AUTOSAR XML (schema 4-2-2)
package /SysDesc/Pkg_Cluster
  can cluster Can_Network_ETAS: baudrate=500000, protocol-name=CAN, protocol-version=1.0, bus-off-recovery={bor-counter-l-1-to-l-2=32, bor-time-l-1=0.01, bor-time-l-2=60.0, bor-time-tx-ensured=1.0, main-function-period=0.001}
    can physical channel Can_Network_ETAS_Channel: comm-connectors=Conn_ETAS_CAN_ETAS
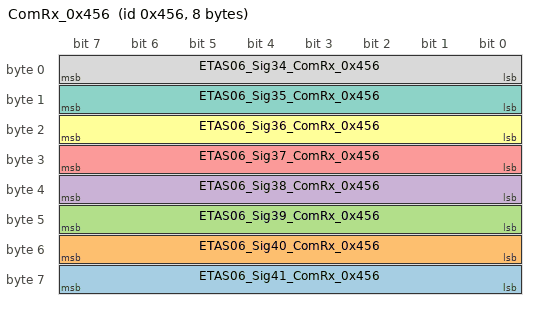
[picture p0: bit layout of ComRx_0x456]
      frame ComRx_0x456: id 0x456, to ETAS, frame-length=8, can-addressing-mode=STANDARD, can-frame-rx-behavior=ANY
        carries pdu ComRx_0x456: packing-byte-order=big-endian, start-position=7, update-indication-bit-position=-1
        pdu ComRx_0x456: length=8, transmission-mode-false-timing=cyclic-timing={time-offset=0, time-period=0.01}, transmission-mode-true-timing=cyclic-timing={time-offset=0, time-period=0.01}
          transmission-mode-conditions:
            {data-filter={data-filter-type=ALWAYS, max=0, min=0, offset=0}, i-signal-in-i-pdu=ETAS06_Sig41}
            {data-filter={data-filter-type=ALWAYS, max=0, min=0, offset=0}, i-signal-in-i-pdu=ETAS06_Sig40}
            {data-filter={data-filter-type=ALWAYS, max=0, min=0, offset=0}, i-signal-in-i-pdu=ETAS06_Sig39}
            {data-filter={data-filter-type=ALWAYS, max=0, min=0, offset=0}, i-signal-in-i-pdu=ETAS06_Sig38}
            {data-filter={data-filter-type=ALWAYS, max=0, min=0, offset=0}, i-signal-in-i-pdu=ETAS06_Sig37}
            {data-filter={data-filter-type=ALWAYS, max=0, min=0, offset=0}, i-signal-in-i-pdu=ETAS06_Sig36}
            {data-filter={data-filter-type=ALWAYS, max=0, min=0, offset=0}, i-signal-in-i-pdu=ETAS06_Sig35}
            {data-filter={data-filter-type=ALWAYS, max=0, min=0, offset=0}, i-signal-in-i-pdu=ETAS06_Sig34}
          signal ETAS06_Sig41_ComRx_0x456: start 63, 8 bit, big-endian, init-value=0, base-type=uint8, compu {phys=raw for raw 0}, update-indication-bit-position=-1, to ETAS
          signal ETAS06_Sig40_ComRx_0x456: start 55, 8 bit, big-endian, init-value=0, base-type=uint8, compu {phys=raw for raw 0}, update-indication-bit-position=-1, to ETAS
          signal ETAS06_Sig39_ComRx_0x456: start 47, 8 bit, big-endian, init-value=0, base-type=uint8, compu {phys=raw for raw 0}, update-indication-bit-position=-1, to ETAS
          signal ETAS06_Sig38_ComRx_0x456: start 39, 8 bit, big-endian, init-value=0, base-type=uint8, compu {phys=raw for raw 0}, update-indication-bit-position=-1, to ETAS
          signal ETAS06_Sig37_ComRx_0x456: start 31, 8 bit, big-endian, init-value=0, base-type=uint8, compu {phys=raw for raw 0}, update-indication-bit-position=-1, to ETAS
          signal ETAS06_Sig36_ComRx_0x456: start 23, 8 bit, big-endian, init-value=0, base-type=uint8, compu {phys=raw for raw 0}, update-indication-bit-position=-1, to ETAS
          signal ETAS06_Sig35_ComRx_0x456: start 15, 8 bit, big-endian, init-value=0, base-type=uint8, compu {phys=raw for raw 0}, update-indication-bit-position=-1, to ETAS
          signal ETAS06_Sig34_ComRx_0x456: start 7, 8 bit, big-endian, init-value=0, base-type=uint8, compu {phys=raw for raw 0}, update-indication-bit-position=-1, to ETAS
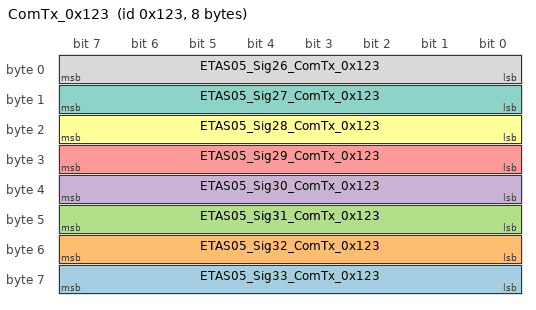
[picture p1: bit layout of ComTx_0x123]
      frame ComTx_0x123: id 0x123, from ETAS, frame-length=8, can-addressing-mode=STANDARD, can-frame-tx-behavior=CAN-20
        carries pdu ComTx_0x123: packing-byte-order=big-endian, start-position=7, update-indication-bit-position=-1
        pdu ComTx_0x123: length=8, transmission-mode-false-timing=cyclic-timing={time-offset=0, time-period=0.1}, transmission-mode-true-timing=cyclic-timing={time-offset=0, time-period=0.1}
          transmission-mode-conditions:
            {data-filter={data-filter-type=ALWAYS, max=0, min=0, offset=0}, i-signal-in-i-pdu=ETAS05_Sig33}
            {data-filter={data-filter-type=ALWAYS, max=0, min=0, offset=0}, i-signal-in-i-pdu=ETAS05_Sig32}
            {data-filter={data-filter-type=ALWAYS, max=0, min=0, offset=0}, i-signal-in-i-pdu=ETAS05_Sig31}
            {data-filter={data-filter-type=ALWAYS, max=0, min=0, offset=0}, i-signal-in-i-pdu=ETAS05_Sig30}
            {data-filter={data-filter-type=ALWAYS, max=0, min=0, offset=0}, i-signal-in-i-pdu=ETAS05_Sig29}
            {data-filter={data-filter-type=ALWAYS, max=0, min=0, offset=0}, i-signal-in-i-pdu=ETAS05_Sig28}
            {data-filter={data-filter-type=ALWAYS, max=0, min=0, offset=0}, i-signal-in-i-pdu=ETAS05_Sig27}
            {data-filter={data-filter-type=ALWAYS, max=0, min=0, offset=0}, i-signal-in-i-pdu=ETAS05_Sig26}
          signal ETAS05_Sig33_ComTx_0x123: start 63, 8 bit, big-endian, init-value=0, base-type=uint8, compu {phys=raw for raw 0}, update-indication-bit-position=-1
          signal ETAS05_Sig32_ComTx_0x123: start 55, 8 bit, big-endian, init-value=0, base-type=uint8, compu {phys=raw for raw 0}, update-indication-bit-position=-1
          signal ETAS05_Sig31_ComTx_0x123: start 47, 8 bit, big-endian, init-value=0, base-type=uint8, compu {phys=raw for raw 0}, update-indication-bit-position=-1
          signal ETAS05_Sig30_ComTx_0x123: start 39, 8 bit, big-endian, init-value=0, base-type=uint8, compu {phys=raw for raw 0}, update-indication-bit-position=-1
          signal ETAS05_Sig29_ComTx_0x123: start 31, 8 bit, big-endian, init-value=0, base-type=uint8, compu {phys=raw for raw 0}, update-indication-bit-position=-1
          signal ETAS05_Sig28_ComTx_0x123: start 23, 8 bit, big-endian, init-value=0, base-type=uint8, compu {phys=raw for raw 0}, update-indication-bit-position=-1
          signal ETAS05_Sig27_ComTx_0x123: start 15, 8 bit, big-endian, init-value=0, base-type=uint8, compu {phys=raw for raw 0}, update-indication-bit-position=-1
          signal ETAS05_Sig26_ComTx_0x123: start 7, 8 bit, big-endian, init-value=0, base-type=uint8, compu {phys=raw for raw 0}, update-indication-bit-position=-1
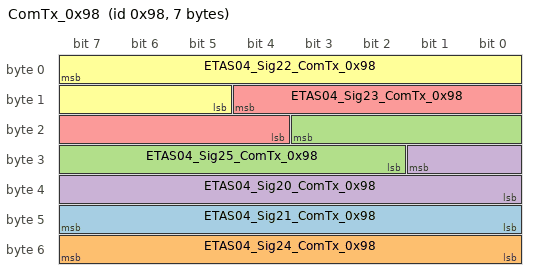
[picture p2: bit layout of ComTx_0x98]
      frame ComTx_0x98: id 0x98, from ETAS, frame-length=7, can-addressing-mode=STANDARD, can-frame-tx-behavior=CAN-20
        carries pdu ComTx_0x98: packing-byte-order=big-endian, start-position=7, update-indication-bit-position=-1
        pdu ComTx_0x98: length=7, transmission-mode-false-timing=cyclic-timing={time-offset=0, time-period=0.05}, transmission-mode-true-timing=cyclic-timing={time-offset=0, time-period=0.05}
          transmission-mode-conditions:
            {data-filter={data-filter-type=NEW-IS-WITHIN, max=254, min=0, offset=0}, i-signal-in-i-pdu=ETAS04_Sig21}
            {data-filter={data-filter-type=NEW-IS-WITHIN, max=254, min=0, offset=0}, i-signal-in-i-pdu=ETAS04_Sig24}
            {data-filter={data-filter-type=NEW-IS-WITHIN, max=1022, min=0, offset=0}, i-signal-in-i-pdu=ETAS04_Sig25}
            {data-filter={data-filter-type=NEW-IS-WITHIN, max=1022, min=0, offset=0}, i-signal-in-i-pdu=ETAS04_Sig20}
            {data-filter={data-filter-type=NEW-IS-WITHIN, max=510, min=0, offset=0}, i-signal-in-i-pdu=ETAS04_Sig23}
            {data-filter={data-filter-type=NEW-IS-WITHIN, max=2046, min=0, offset=0}, i-signal-in-i-pdu=ETAS04_Sig22}
          signal ETAS04_Sig21_ComTx_0x98: start 47, 8 bit, big-endian, init-value=40, base-type=uint8, compu {phys=raw-40 for raw 0..254; unit deg}, update-indication-bit-position=-1  # IGBT温度
          signal ETAS04_Sig24_ComTx_0x98: start 55, 8 bit, big-endian, init-value=40, base-type=uint8, compu {phys=raw-40 for raw 0..254; unit deg}, update-indication-bit-position=-1  # 电机温度
          signal ETAS04_Sig25_ComTx_0x98: start 19, 10 bit, big-endian, init-value=0, base-type=uint16, compu {phys=raw for raw 0..1022; unit V}, update-indication-bit-position=-1  # 母线电压
          signal ETAS04_Sig20_ComTx_0x98: start 25, 10 bit, big-endian, init-value=511, base-type=uint16, compu {phys=raw-511 for raw 0..1022; unit A}, update-indication-bit-position=-1  # 母线电流
          signal ETAS04_Sig23_ComTx_0x98: start 12, 9 bit, big-endian, init-value=0, base-type=uint16, compu {phys=raw for raw 0..510; unit Nm}, update-indication-bit-position=-1  # 最小扭矩
          signal ETAS04_Sig22_ComTx_0x98: start 7, 11 bit, big-endian, init-value=0, base-type=uint16, compu {phys=raw for raw 0..2046; unit Nm}, update-indication-bit-position=-1  # 最大扭矩
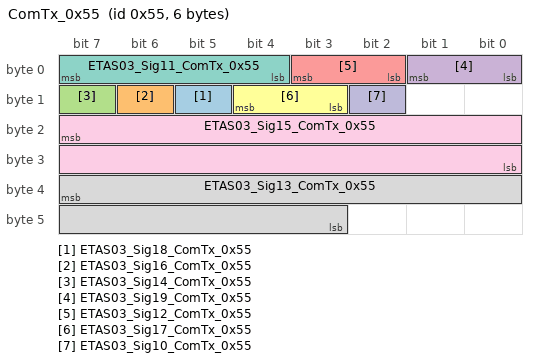
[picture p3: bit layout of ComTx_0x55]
      frame ComTx_0x55: id 0x55, from ETAS, frame-length=6, can-addressing-mode=STANDARD, can-frame-tx-behavior=CAN-20
        carries pdu ComTx_0x55: packing-byte-order=big-endian, start-position=7, update-indication-bit-position=-1
        pdu ComTx_0x55: length=6, transmission-mode-false-timing=cyclic-timing={time-offset=0, time-period=0.01}, transmission-mode-true-timing=cyclic-timing={time-offset=0, time-period=0.01}
          transmission-mode-conditions:
            {data-filter={data-filter-type=ALWAYS, max=1, min=0, offset=0}, i-signal-in-i-pdu=ETAS03_Sig18}
            {data-filter={data-filter-type=ALWAYS, max=1, min=0, offset=0}, i-signal-in-i-pdu=ETAS03_Sig16}
            {data-filter={data-filter-type=ALWAYS, max=1, min=0, offset=0}, i-signal-in-i-pdu=ETAS03_Sig14}
            {data-filter={data-filter-type=ALWAYS, max=3, min=0, offset=0}, i-signal-in-i-pdu=ETAS03_Sig19}
            {data-filter={data-filter-type=ALWAYS, max=3, min=0, offset=0}, i-signal-in-i-pdu=ETAS03_Sig12}
            {data-filter={data-filter-type=ALWAYS, max=3, min=0, offset=0}, i-signal-in-i-pdu=ETAS03_Sig17}
            {data-filter={data-filter-type=ALWAYS, max=3, min=0, offset=0}, i-signal-in-i-pdu=ETAS03_Sig11}
            {data-filter={data-filter-type=NEW-IS-WITHIN, max=8189, min=0, offset=0}, i-signal-in-i-pdu=ETAS03_Sig13}
            {data-filter={data-filter-type=NEW-IS-WITHIN, max=65534, min=0, offset=0}, i-signal-in-i-pdu=ETAS03_Sig15}
            {data-filter={data-filter-type=ALWAYS, max=1, min=0, offset=0}, i-signal-in-i-pdu=ETAS03_Sig10}
          signal ETAS03_Sig18_ComTx_0x55: start 13, 1 bit, big-endian, init-value=0, base-type=uint8, compu {phys=raw for raw 0..1, 0=FORBIDDING, 1=ALLOWING}, update-indication-bit-position=-1  # 允许下电
          signal ETAS03_Sig16_ComTx_0x55: start 14, 1 bit, big-endian, init-value=0, base-type=uint8, compu-method=CompuMethod_ETAS03_Sig16_ComTx_0x55, update-indication-bit-position=-1  # 高压上电完成
          signal ETAS03_Sig14_ComTx_0x55: start 15, 1 bit, big-endian, init-value=0, base-type=uint8, compu {phys=raw for raw 0..1, 0=FORBIDDINGTOTURNONHV, 1=ALLOWINGTOTURNONHV}, update-indication-bit-position=-1  # 允许高压上电
          signal ETAS03_Sig19_ComTx_0x55: start 1, 2 bit, big-endian, init-value=0, base-type=uint8, compu-method=CompuMethod_ETAS03_Sig19_ComTx_0x55, update-indication-bit-position=-1  # 电机工作状态
          signal ETAS03_Sig12_ComTx_0x55: start 3, 2 bit, big-endian, init-value=0, base-type=uint8, compu-method=CompuMethod_ETAS03_Sig12_ComTx_0x55, update-indication-bit-position=-1  # 电机快速放电状态
          signal ETAS03_Sig17_ComTx_0x55: start 12, 2 bit, big-endian, init-value=0, base-type=uint8, compu {phys=raw for raw 0..3, 0=DEFAULT, 1=SIG16ING, 2=OK, 3=FAILED}, update-indication-bit-position=-1  # MCU自检
          signal ETAS03_Sig11_ComTx_0x55: start 7, 4 bit, big-endian, init-value=0, base-type=uint8, compu {phys=raw for raw 0..3}, update-indication-bit-position=-1  # 报文滚码信息
          signal ETAS03_Sig13_ComTx_0x55: start 39, 13 bit, big-endian, init-value=4094, base-type=uint16, compu {phys=raw*0.5-2047 for raw 0..8189; unit Nm}, update-indication-bit-position=-1  # 电机当前扭矩
          signal ETAS03_Sig15_ComTx_0x55: start 23, 16 bit, big-endian, init-value=32767, base-type=uint16, compu {phys=raw-32767 for raw 0..65534; unit rpm}, update-indication-bit-position=-1  # 电机当前转速
          signal ETAS03_Sig10_ComTx_0x55: start 10, 1 bit, big-endian, init-value=0, base-type=uint8, compu {phys=raw for raw 0..1, 0=NORMAL, 1=SIG04}, update-indication-bit-position=-1  # 紧急下电请求
      frame ComRx_0x261: id 0x261, to ETAS, frame-length=1, can-addressing-mode=STANDARD, can-frame-rx-behavior=ANY
        carries pdu ComRx_0x261: packing-byte-order=big-endian, start-position=7, update-indication-bit-position=-1
        pdu ComRx_0x261: length=1, transmission-mode-condition{data-filter={data-filter-type=ALWAYS, max=1, min=0, offset=0}, i-signal-in-i-pdu=ETAS02_Sig09}, transmission-mode-false-timing=cyclic-timing={time-offset=0, time-period=0.01}, transmission-mode-true-timing=cyclic-timing={time-offset=0, time-period=0.01}
          signal ETAS02_Sig09_ComRx_0x261: start 0, 1 bit, big-endian, init-value=0, base-type=uint8, compu {phys=raw for raw 0..1, 0=NORMAL, 1=SLEEP}, update-indication-bit-position=-1, to ETAS  # ETAS低压下电
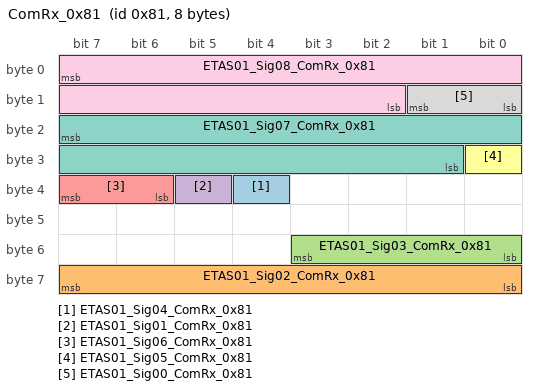
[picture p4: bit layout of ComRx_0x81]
      frame ComRx_0x81: id 0x81, to ETAS, frame-length=8, can-addressing-mode=STANDARD, can-frame-rx-behavior=ANY
        carries pdu ComRx_0x81: packing-byte-order=big-endian, start-position=7, update-indication-bit-position=-1
        pdu ComRx_0x81: length=8, transmission-mode-false-timing=cyclic-timing={time-offset=0, time-period=0.01}, transmission-mode-true-timing=cyclic-timing={time-offset=0, time-period=0.01}
          transmission-mode-conditions:
            {data-filter={data-filter-type=ALWAYS, max=1, min=0, offset=0}, i-signal-in-i-pdu=ETAS01_Sig04}
            {data-filter={data-filter-type=ALWAYS, max=255, min=0, offset=0}, i-signal-in-i-pdu=ETAS01_Sig02}
            {data-filter={data-filter-type=ALWAYS, max=15, min=0, offset=0}, i-signal-in-i-pdu=ETAS01_Sig03}
            {data-filter={data-filter-type=ALWAYS, max=1, min=0, offset=0}, i-signal-in-i-pdu=ETAS01_Sig01}
            {data-filter={data-filter-type=ALWAYS, max=3, min=0, offset=0}, i-signal-in-i-pdu=ETAS01_Sig06}
            {data-filter={data-filter-type=ALWAYS, max=1, min=0, offset=0}, i-signal-in-i-pdu=ETAS01_Sig05}
            {data-filter={data-filter-type=NEW-IS-WITHIN, max=32767, min=0, offset=0}, i-signal-in-i-pdu=ETAS01_Sig07}
            {data-filter={data-filter-type=ALWAYS, max=3, min=0, offset=0}, i-signal-in-i-pdu=ETAS01_Sig00}
            {data-filter={data-filter-type=NEW-IS-WITHIN, max=16383, min=0, offset=0}, i-signal-in-i-pdu=ETAS01_Sig08}
          signal ETAS01_Sig04_ComRx_0x81: start 36, 1 bit, big-endian, init-value=0, base-type=uint8, compu {phys=raw for raw 0..1, 0=FORBIDDING, 1=ALLOWING}, update-indication-bit-position=-1, to ETAS  # MCU使能信号
          signal ETAS01_Sig02_ComRx_0x81: start 63, 8 bit, big-endian, init-value=0, base-type=uint8, compu {phys=raw for raw 0..255}, update-indication-bit-position=-1, to ETAS  # 检查
          signal ETAS01_Sig03_ComRx_0x81: start 51, 4 bit, big-endian, init-value=0, base-type=uint8, compu {phys=raw for raw 0..15}, update-indication-bit-position=-1, to ETAS  # 滚码信息
          signal ETAS01_Sig01_ComRx_0x81: start 37, 1 bit, big-endian, init-value=0, base-type=uint8, compu {phys=raw for raw 0..1, 0=FORBIDDING, 1=ALLOWING}, update-indication-bit-position=-1, to ETAS  # MCU主动放电
          signal ETAS01_Sig06_ComRx_0x81: start 39, 2 bit, big-endian, init-value=0, base-type=uint8, compu-method=CompuMethod_ETAS01_Sig06_ComRx_0x81, update-indication-bit-position=-1, to ETAS  # 电机工作模式请求
          signal ETAS01_Sig05_ComRx_0x81: start 24, 1 bit, big-endian, init-value=0, base-type=uint8, compu {phys=raw for raw 0..1, 0=FORBIDDING, 1=ALLOWING}, update-indication-bit-position=-1, to ETAS  # MCU使能信号
          signal ETAS01_Sig07_ComRx_0x81: start 23, 15 bit, big-endian, init-value=16384, base-type=uint16, compu {phys=raw-16384 for raw 0..32767; unit rpm}, update-indication-bit-position=-1, to ETAS  # 需求转速
          signal ETAS01_Sig00_ComRx_0x81: start 9, 2 bit, big-endian, init-value=0, base-type=uint8, compu {phys=raw for raw 0..3, 0=N, 1=R, 2=D, 3=P}, update-indication-bit-position=-1, to ETAS  # 当前整车档位信息
          signal ETAS01_Sig08_ComRx_0x81: start 7, 14 bit, big-endian, init-value=8192, base-type=uint16, compu {phys=raw*0.25-2048 for raw 0..16383; unit Nm}, update-indication-bit-position=-1, to ETAS  # ETAS对MCU扭矩请求
      frame NM_Rx_0x677: id 0x677, to ETAS, frame-length=8, can-addressing-mode=STANDARD, can-frame-rx-behavior=ANY
        carries pdu NM_Rx_0x677: packing-byte-order=big-endian, start-position=7, update-indication-bit-position=-1
        nm pdu NM_Rx_0x677: length=8, nm-data-information=false, nm-vote-information=false
          signal NM_Rx_Sig_NM_Rx_0x677: start 23, 8 bit, big-endian, init-value=0, base-type=uint8, compu {phys=raw for raw 0..255}, update-indication-bit-position=-1, to ETAS
      frame NM_Tx_0x600: id 0x600, from ETAS, frame-length=8, can-addressing-mode=STANDARD, can-frame-tx-behavior=CAN-20
        carries pdu NM_Tx_0x600: packing-byte-order=big-endian, start-position=7, update-indication-bit-position=-1
        nm pdu NM_Tx_0x600: length=8, nm-data-information=false, nm-vote-information=false
          signal NM_Tx_Sig_NM_Tx_0x600: start 23, 8 bit, big-endian, init-value=0, base-type=uint8, compu {phys=raw for raw 0..255}, update-indication-bit-position=-1
      frame XcpTx_0x333: id 0x333, from ETAS, frame-length=8, can-addressing-mode=STANDARD, can-frame-tx-behavior=CAN-20
        carries pdu XcpTx_0x333: packing-byte-order=big-endian, start-position=7, update-indication-bit-position=-1
        general purpose i pdu XcpTx_0x333: category=XCP, length=8
      frame XcpRx_0x332: id 0x332, to ETAS, frame-length=8, can-addressing-mode=STANDARD, can-frame-rx-behavior=ANY
        carries pdu XcpRx_0x332: packing-byte-order=big-endian, start-position=7, update-indication-bit-position=-1
        general purpose i pdu XcpRx_0x332: category=XCP, length=8
      frame UdsRxFnc: id 0x7DF, to ETAS, frame-length=8, can-addressing-mode=STANDARD, can-frame-rx-behavior=ANY
        carries pdu NPdu_UdsRxFnc: packing-byte-order=big-endian, start-position=7, update-indication-bit-position=-1
        n pdu NPdu_UdsRxFnc: length=8
      frame UdsRxPhy: id 0x740, to ETAS, frame-length=8, can-addressing-mode=STANDARD, can-frame-rx-behavior=ANY
        carries pdu NPdu_UdsRxPhy: packing-byte-order=big-endian, start-position=7, update-indication-bit-position=-1
        n pdu NPdu_UdsRxPhy: length=8
      frame UdsTxPhy: id 0x748, from ETAS, frame-length=8, can-addressing-mode=STANDARD, can-frame-tx-behavior=CAN-20
        carries pdu NPdu_UdsTxPhy: packing-byte-order=big-endian, start-position=7, update-indication-bit-position=-1
        n pdu NPdu_UdsTxPhy: length=8
      pdu triggering PduTrig_UdsRxFnc: pdu=UdsRxFnc, to ETAS
      pdu triggering PduTrig_UdsRxPhy: pdu=UdsRxPhy, to ETAS
      pdu triggering PduTrig_UdsTxPhy: pdu=UdsTxPhy, from ETAS
package /SysDesc/Pkg_Pdus
  dcm i pdu UdsRxFnc: length=8, diag-pdu-type=DIAG-REQUEST
  dcm i pdu UdsRxPhy: length=8, diag-pdu-type=DIAG-REQUEST
  dcm i pdu UdsTxPhy: length=8, diag-pdu-type=DIAG-RESPONSE
package /SysDesc/Pkg_Nm
  nm config NmConfig_0
    can nm cluster CanNmCluster_ETAS_CAN:
      communication-cluster=Can_Network_ETAS
      nm-channel-id=1
      nm-channel-sleep-master=false
      nm-node-detection-enabled=true
      nm-node-id-enabled=true
      nm-synchronizing-network=false
      nm-busload-reduction-active=false
      nm-car-wake-up-filter-enabled=false
      nm-car-wake-up-rx-enabled=false
      nm-cbv-position=1
      nm-channel-active=true
      nm-immediate-nm-cycle-time=0.02
      nm-immediate-nm-transmissions=20
      nm-message-timeout-time=0.5
      nm-msg-cycle-time=1.0
      nm-network-timeout=3.0
      nm-nid-position=0
      nm-remote-sleep-indication-time=0.01
      nm-repeat-message-time=1.0
      nm-user-data-length=6
      nm-wait-bus-sleep-time=4.0
      can nm node CanNmNode_ETAS_ETAS_CAN: controller=ETAS_CAN, nm-coordinator-role=PASSIVE, nm-if-ecu=NmEcu_ETAS, nm-node-id=0, nm-passive-mode-enabled=false, nm-msg-cycle-offset=0.1, nm-msg-reduced-time=0.5, rx-nm-pdu=NM_Rx_0x677, tx-nm-pdu=NM_Tx_0x600, nm-range-config={lower-can-id=1536, upper-can-id=1655}
    nm-if-ecus:
      nm ecu NmEcu_ETAS:
        bus-specific-nm-ecu=can-nm-ecu=nm-repeat-msg-indication-enabled=false
        ecu-instance=ETAS
        nm-bus-synchronization-enabled=false
        nm-com-control-enabled=true
        nm-coordinator=nm-node=CanNmNode_ETAS_ETAS_CAN
        nm-cycletime-main-function=0.01
        nm-multiple-channels-enabled=false
        nm-node-detection-enabled=true
        nm-node-id-enabled=true
        nm-passive-mode-enabled=false
        nm-pdu-rx-indication-enabled=true
        nm-remote-sleep-ind-enabled=false
        nm-repeat-msg-ind-enabled=false
        nm-state-change-ind-enabled=true
        nm-user-data-enabled=true
package /SysDesc/Pkg_Ecu
  ecu instance ETAS: com-configuration-gw-time-base=0.005, com-configuration-rx-time-base=0.01, com-configuration-tx-time-base=0.01, sleep-mode-supported=false, wake-up-over-bus-supported=false
    can communication controller ETAS_CAN: can-controller-attributes=can-controller-configuration={prop-seg=0, sync-jump-width=0, time-seg-1=10, time-seg-2=0}
    can communication connector Conn_ETAS_CAN_ETAS: comm-controller=ETAS_CAN
package /SysDesc/Pkg_CompuMethod
  compu method CompuMethod_ETAS03_Sig16_ComTx_0x55: phys=raw for raw 0..1, 0=FORBIDDINGGETTINGTORQUECMD, 1=ALLOWMCUTOGETTORQUECOMMAND
  compu method CompuMethod_ETAS03_Sig19_ComTx_0x55: phys=raw for raw 0..3, 0=NORMAL, 1=WARNING(DERATING (WARNING_DERATING), 2=RECOVERABLEFAULT, 3=NORECOVERABLEFAULT
  compu method CompuMethod_ETAS03_Sig12_ComTx_0x55: phys=raw for raw 0..3, 0=DEFAULT, 1=DISCHARGING, 2=DISCHARGEFINISHED, 3=RESERVED
  compu method CompuMethod_ETAS01_Sig06_ComRx_0x81: phys=raw for raw 0..3, 0=DEFAULT, 1=TORQUEMODE, 2=SPEEDMODE, 3=RESERVED
  compu method CompuMethod_XcpTx_Sig_XcpTx_0x333: phys=raw for raw 0..255
  compu method CompuMethod_XcpRx_Sig_XcpRx_0x332: phys=raw for raw 0..255
  compu method CompuMethod_UdsRxFnc_Sig_UdsRxFnc: phys=raw for raw 0..255
  compu method CompuMethod_UdsRxPhy_Sig_UdsRxPhy: phys=raw for raw 0..255
  compu method CompuMethod_UdsTxPhy_Sig_UdsTxPhy: phys=raw for raw 0..255
package /SysDesc/Pkg_Units
  5 x unit:
    deg
    V
    A
    Nm
    rpm
